# PIC32MM0064GPL020 device description
Architecture: MIPS; Family: PIC32MM1324; Series: PIC32MM
Registers are 32-bit, read-write, no defined reset value unless marked. A register's access mark holds for its fields unless they carry their own. Offsets are from the block's base; [hi:lo] are bit positions; {n}, {i} and the like mark numbered series; 'fields as' and 'values as' point back to an identical list.

## CFG
Instances: CFG 0x1f802300 in periph0
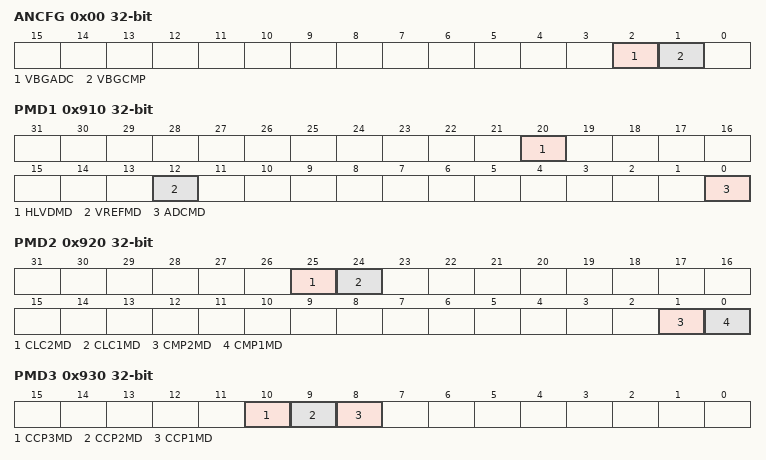
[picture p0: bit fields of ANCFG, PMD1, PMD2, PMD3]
0x00 ANCFG
  [2] VBGADC, [1] VBGCMP
0x900 PMDCON
  [11] PMDLOCK
0x910 PMD1
  [20] HLVDMD, [12] VREFMD, [0] ADCMD
0x920 PMD2
  [25] CLC2MD, [24] CLC1MD, [1] CMP2MD, [0] CMP1MD
0x930 PMD3
  [10] CCP3MD, [9] CCP2MD, [8] CCP1MD
0x940 PMD4
  [0] T1MD
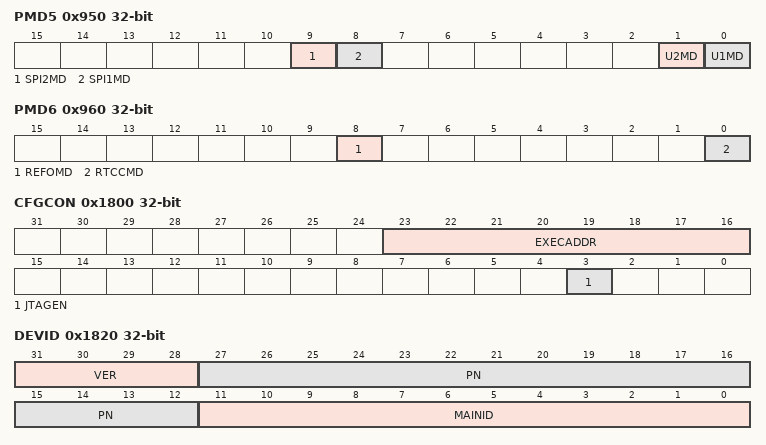
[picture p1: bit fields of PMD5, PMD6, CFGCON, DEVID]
0x950 PMD5
  [9] SPI2MD, [8] SPI1MD, [1] U2MD, [0] U1MD
0x960 PMD6
  [8] REFOMD, [0] RTCCMD
0x970 PMD7
  [3] CRCMD
0x1800 CFGCON
  [23:16] EXECADDR, [3] JTAGEN
0x1820 DEVID ro
  [31:28] VER, [27:12] PN, [11:0] MAINID
0x1830 SYSKEY wo

## CLC
Instances: CLC 0x1f800a80 in periph0
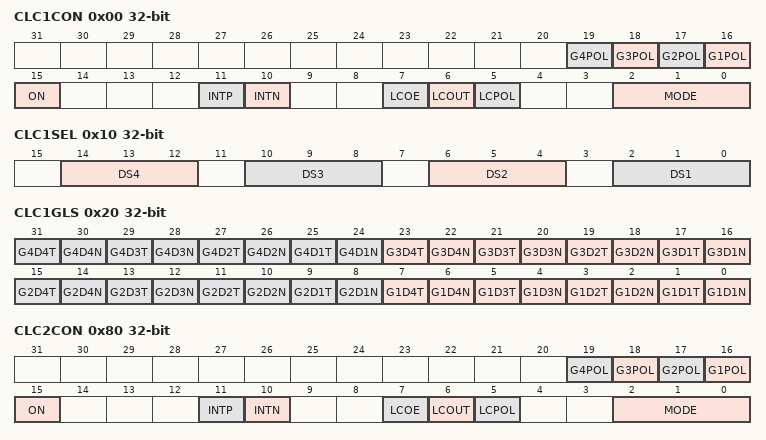
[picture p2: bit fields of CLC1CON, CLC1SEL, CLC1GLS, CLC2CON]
0x00 CLC1CON
  [n+15] G{n}POL (n=1..4) — Gate {n} Polarity Control bit
    1=The output of Channel {n} logic is inverted when applied to the logic cell; 0=The output of Channel {n} logic is not inverted
  [15] ON — CLCx Enable bit
    1=CLCx is enabled and mixing input signals; 0=CLCx is disabled and has logic zero outputs
  [11] INTP — CLCx Positive Edge Interrupt Enable bit
    1=Interrupt will be generated when a rising edge occurs on LCOUT; 0=Interrupt will not be generated
  [10] INTN — CLCx Negative Edge Interrupt Enable bit
    1=Interrupt will be generated when a falling edge occurs on LCOUT; 0=Interrupt will not be generated
  [7] LCOE — CLCx Port Enable bit
    1=CLCx port pin output is enabled; 0=CLCx port pin output is disabled
  [6] LCOUT — CLCx Data Output Status bit
    1=CLCx output high; 0=CLCx output low
  [5] LCPOL — CLCx Output Polarity Control bit
    1=The output of the module is inverted; 0=The output of the module is not inverted
  [2:0] MODE — CLCx Mode bits
    7=Cell is a 1-input transparent latch with S and R; 6=Cell is a JK flip-flop with R; 5=Cell is a 2-input D flip-flop with R; 4=Cell is a 1-input D flip-flop with S and R; 3=Cell is an SR latch; 2=Cell is a 4-input AND; 1=Cell is an OR-XOR; 0=Cell is a AND-OR
0x10 CLC1SEL
  [14:12] DS4 — Data Selection MUX 4 Signal Selection bits
    7=SCCP3 OCMP compare match event; 6=MCCP1 OCMP compare match event; 5=RTCC event; 3=SPI1 SDI1 in; 2=SCCP3 OCM3 output; 1=CLC2 out; 0=CLCINB I/O pin
  [10:8] DS3 — Data Selection MUX 3 Signal Selection bits
    7=SCCP3 OCMP compare match event; 6=SCCP2 OCMP compare match event; 5=SCCP2 OCM2 output; 4=UART1 RX In; 3=SPI1 SDO1 Out; 2=CMP2 out; 1=CLC1 Out; 0=CLCINA I/O pin
  [6:4] DS2 — Data Selection MUX 2 Signal Selection bits
    6=MCCP1 OCMP compare match event; 4=ADC End of Conversion; 3=UART1 TX Out; 2=CMP1 out; 1=CLC2 out; 0=CLCINB I/O pin
  [2:0] DS1 — Data Selection MUX 1 Signal Selection bits
    7=MCCP1 OCM1C Output; 6=MCCP1 OCM1B Output; 5=MCCP1 OCM1A Output; 4=REFO1 Clock Output; 3=LPRC Clock; 2=SOSC Clock; 1=System Clock; 0=CLCINA I/O pin
0x20 CLC1GLS
  [8n-1] G{n}D4T (n=1..4), [8n-2] G{n}D4N (n=1..4), [8n-3] G{n}D3T (n=1..4), [8n-4] G{n}D3N (n=1..4), [8n-5] G{n}D2T (n=1..4), [8n-6] G{n}D2N (n=1..4), [8n-7] G{n}D1T (n=1..4), [8n-8] G{n}D1N (n=1..4)
0x80 CLC2CON
  fields as CLC1CON
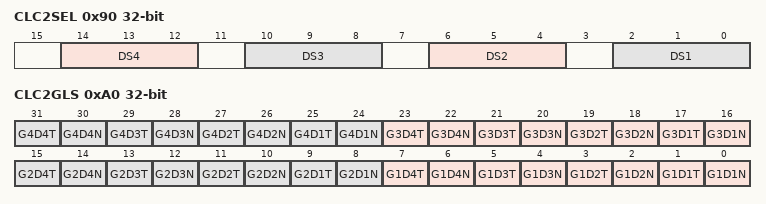
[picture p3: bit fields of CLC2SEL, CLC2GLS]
0x90 CLC2SEL
  [14:12] DS4 — Data Selection MUX 4 Signal Selection bits
    7=SCCP3 OCMP compare match event; 6=MCCP1 OCMP compare match event; 5=RTCC event; 3=SPI2 SDI2 in; 2=SCCP3 OCM3 Output; 1=CLC1 out; 0=CLCINB I/O pin
  [10:8] DS3 — Data Selection MUX 3 Signal Selection bits
    7=SCCP3 OCMP compare match event; 6=SCCP2 OCMP compare match event; 5=SCCP2 OCM2 output; 4=UART2 RX In; 3=SPI2 SDO2 Out; 2=CMP2 out; 1=CLC2 Out; 0=CLCINA I/O pin
  [6:4] DS2 — Data Selection MUX 2 Signal Selection bits
    6=MCCP1 OCMP compare match event; 4=ADC End of Conversion; 3=UART2 TX Out; 2=CMP1 out; 1=CLC1 out; 0=CLCINB I/O pin
  [2:0] DS1 — Data Selection MUX 1 Signal Selection bits
    7=MCCP1 OCM1F Output; 6=MCCP1 OCM1E Output; 5=MCCP1 OCM1D Output; 4=REFO1 Clock Output; 3=LPRC Clock; 2=SOSC Clock; 1=System Clock; 0=CLCINA I/O pin
0xA0 CLC2GLS
  fields as CLC1GLS
